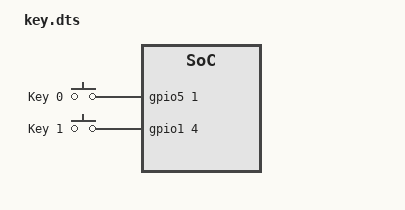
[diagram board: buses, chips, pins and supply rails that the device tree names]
/*
 * Copyright (C) 2019 - All Rights Reserved by 
 * filename : imx-fire-key-overlay.dts
 * brief : Device Tree overlay for EBF6ull key device
 * author : embedfire
 * date : 2019-12-10
 * version : A001
 */
#include "imx6ul-pinfunc.h"
#include "imx6ull-pinfunc-snvs.h"
#include "dt-bindings/input/linux-event-codes.h"
#include "dt-bindings/gpio/gpio.h"

/dts-v1/;
/plugin/;

/{
	
	fragment@0 {
		target-path = "/";
		__overlay__ {
			sgpio-keys {
					compatible = "gpio-keys";

					Key0{
						pinctrl-names = "default";
						pinctrl-0 = <&pinctrl_gpio_key0>;
						label = "Key 0";
						gpios = <&gpio5 1 GPIO_ACTIVE_HIGH>;
						linux,code=<KEY_0>;
					};
					Key1{
						pinctrl-names = "default";
						pinctrl-0 = <&pinctrl_gpio_key1>;
						label = "Key 1";
						gpios = <&gpio1 4 GPIO_ACTIVE_HIGH>;
						linux,code=<KEY_1>;
					};				
			};			
		};
	};
	
	fragment@1 {
		target = <&iomuxc_snvs>;
		__overlay__ {	
			pinctrl_gpio_key0: key0sgrp{
				fsl,pins = <
					MX6UL_PAD_SNVS_TAMPER1__GPIO5_IO01      0x000110A1
				>;
				};
			pinctrl_gpio_key1: key1sgrp{
				fsl,pins = <
					MX6UL_PAD_GPIO1_IO04__GPIO1_IO04        0x000110A1
				>;
			};	
		};
	};
};
